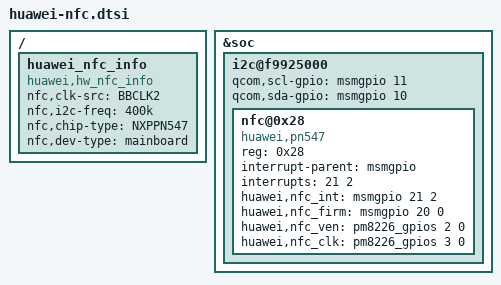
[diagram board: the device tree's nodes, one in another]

 / {
        huawei_nfc_info {
                  compatible = "huawei,hw_nfc_info";
	           nfc,clk-src = "BBCLK2";
	           nfc,i2c-freq = "400k";
		    nfc,chip-type = "NXPPN547";
		    nfc,dev-type = "mainboard";
                  status = "ok";
        };
};


&soc {
	i2c@f9925000 { /* BLSP1 QUP3 */
		qcom,scl-gpio = <&msmgpio 11 0>;
		qcom,sda-gpio = <&msmgpio 10 0>;
		
	    nfc@0x28 {
		status = "ok";
		reg = <0x28>;
		compatible = "huawei,pn547";
              interrupt-parent = <&msmgpio>;
		interrupts = <21 2>; /*1 = low-to-high edge triggered
     		                                 2 = high-to-low edge triggered
     		                                 4 = active high level-sensitive
     		                                 8 = active low level-sensitive */
		huawei,nfc_int = <&msmgpio 21 2>;
		
		huawei,nfc_firm = <&msmgpio 20 0>;
		huawei,nfc_ven = <&pm8226_gpios 2 0>;
		huawei,nfc_clk = <&pm8226_gpios 3 0>;
	    };
	};
};
        	
